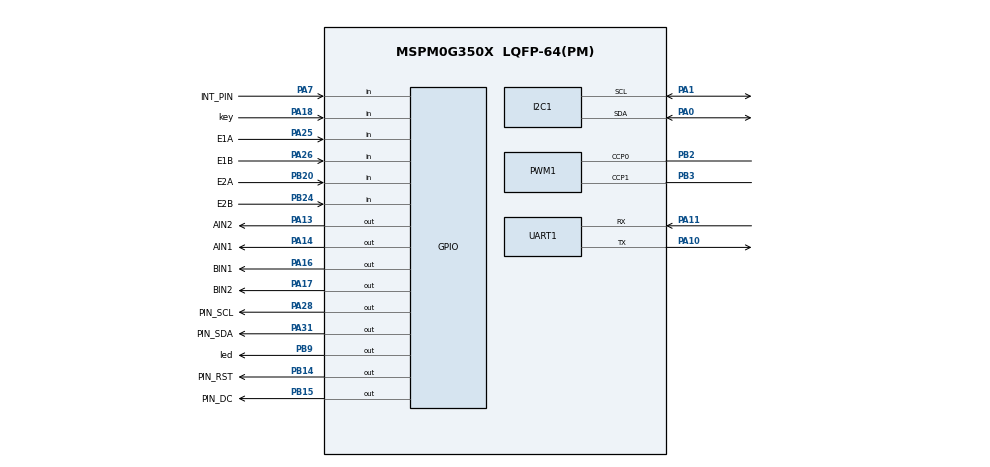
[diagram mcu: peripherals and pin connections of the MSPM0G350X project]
/**
 * @cliArgs --device "MSPM0G350X" --package "LQFP-64(PM)" --part "Default" --product "mspm0_sdk@2.01.00.03"
 * @versions {"tool":"1.20.0+3587"}
 */

/**
 * Import the modules used in this configuration.
 */
const GPIO    = scripting.addModule("/ti/driverlib/GPIO", {}, false);
const GPIO1   = GPIO.addInstance();
const GPIO2   = GPIO.addInstance();
const GPIO3   = GPIO.addInstance();
const GPIO4   = GPIO.addInstance();
const GPIO5   = GPIO.addInstance();
const GPIO6   = GPIO.addInstance();
const GPIO7   = GPIO.addInstance();
const GPIO8   = GPIO.addInstance();
const GPIO9   = GPIO.addInstance();
const GPIO10  = GPIO.addInstance();
const GPIO11  = GPIO.addInstance();
const GPIO12  = GPIO.addInstance();
const GPIO13  = GPIO.addInstance();
const GPIO14  = GPIO.addInstance();
const GPIO15  = GPIO.addInstance();
const I2C     = scripting.addModule("/ti/driverlib/I2C", {}, false);
const I2C1    = I2C.addInstance();
const PWM     = scripting.addModule("/ti/driverlib/PWM", {}, false);
const PWM1    = PWM.addInstance();
const SYSCTL  = scripting.addModule("/ti/driverlib/SYSCTL");
const SYSTICK = scripting.addModule("/ti/driverlib/SYSTICK");
const TIMER   = scripting.addModule("/ti/driverlib/TIMER", {}, false);
const TIMER1  = TIMER.addInstance();
const UART    = scripting.addModule("/ti/driverlib/UART", {}, false);
const UART1   = UART.addInstance();

/**
 * Write custom configuration values to the imported modules.
 */
const divider7       = system.clockTree["PLL_PDIV"];
divider7.divideValue = 2;

const divider9       = system.clockTree["UDIV"];
divider9.divideValue = 2;

const gate7  = system.clockTree["MFCLKGATE"];
gate7.enable = true;

const gate8  = system.clockTree["MFPCLKGATE"];
gate8.enable = true;

const multiplier2         = system.clockTree["PLL_QDIV"];
multiplier2.multiplyValue = 5;

const mux2       = system.clockTree["CANCLKMUX"];
mux2.inputSelect = "CANCLKMUX_PLLCLK1_OUT";

const mux8       = system.clockTree["HSCLKMUX"];
mux8.inputSelect = "HSCLKMUX_SYSPLL2X";

GPIO1.$name                         = "MPU6050";
GPIO1.associatedPins[0].$name       = "INT_PIN";
GPIO1.associatedPins[0].direction   = "INPUT";
GPIO1.associatedPins[0].interruptEn = true;
GPIO1.associatedPins[0].polarity    = "FALL";
GPIO1.associatedPins[0].pin.$assign = "PA7";

const Board = scripting.addModule("/ti/driverlib/Board", {}, false);

GPIO2.$name                               = "ENCODERA";
GPIO2.associatedPins.create(2);
GPIO2.associatedPins[0].$name             = "E1A";
GPIO2.associatedPins[0].direction         = "INPUT";
GPIO2.associatedPins[0].interruptEn       = true;
GPIO2.associatedPins[0].interruptPriority = "0";
GPIO2.associatedPins[0].polarity          = "RISE";
GPIO2.associatedPins[0].pin.$assign       = "PA25";
GPIO2.associatedPins[1].$name             = "E1B";
GPIO2.associatedPins[1].direction         = "INPUT";
GPIO2.associatedPins[1].interruptEn       = true;
GPIO2.associatedPins[1].interruptPriority = "0";
GPIO2.associatedPins[1].polarity          = "RISE";
GPIO2.associatedPins[1].pin.$assign       = "PA26";

GPIO3.$name                               = "ENCODERB";
GPIO3.associatedPins.create(2);
GPIO3.associatedPins[0].direction         = "INPUT";
GPIO3.associatedPins[0].$name             = "E2A";
GPIO3.associatedPins[0].interruptEn       = true;
GPIO3.associatedPins[0].interruptPriority = "0";
GPIO3.associatedPins[0].polarity          = "RISE";
GPIO3.associatedPins[0].pin.$assign       = "PB20";
GPIO3.associatedPins[1].$name             = "E2B";
GPIO3.associatedPins[1].direction         = "INPUT";
GPIO3.associatedPins[1].interruptEn       = true;
GPIO3.associatedPins[1].interruptPriority = "0";
GPIO3.associatedPins[1].polarity          = "RISE";
GPIO3.associatedPins[1].pin.$assign       = "PB24";

GPIO4.$name                         = "AIN";
GPIO4.port                          = "PORTA";
GPIO4.associatedPins.create(2);
GPIO4.associatedPins[0].$name       = "AIN1";
GPIO4.associatedPins[0].pin.$assign = "PA14";
GPIO4.associatedPins[1].$name       = "AIN2";
GPIO4.associatedPins[1].pin.$assign = "PA13";

GPIO5.$name                         = "BIN";
GPIO5.port                          = "PORTA";
GPIO5.associatedPins.create(2);
GPIO5.associatedPins[0].$name       = "BIN1";
GPIO5.associatedPins[0].pin.$assign = "PA16";
GPIO5.associatedPins[1].$name       = "BIN2";
GPIO5.associatedPins[1].pin.$assign = "PA17";

GPIO6.$name                         = "LED";
GPIO6.associatedPins[0].$name       = "led";
GPIO6.associatedPins[0].pin.$assign = "PB9";

GPIO7.$name                         = "KEY";
GPIO7.associatedPins[0].$name       = "key";
GPIO7.associatedPins[0].direction   = "INPUT";
GPIO7.associatedPins[0].pin.$assign = "PA18";

GPIO8.$name                         = "OLED_RST";
GPIO8.associatedPins[0].$name       = "PIN_RST";
GPIO8.associatedPins[0].pin.$assign = "PB14";

GPIO9.$name                         = "OLED_DC";
GPIO9.associatedPins[0].$name       = "PIN_DC";
GPIO9.associatedPins[0].pin.$assign = "PB15";

GPIO10.$name                         = "OLED_SCL";
GPIO10.associatedPins[0].$name       = "PIN_SCL";
GPIO10.associatedPins[0].pin.$assign = "PA28";

GPIO11.$name                         = "OLED_SDA";
GPIO11.associatedPins[0].$name       = "PIN_SDA";
GPIO11.associatedPins[0].pin.$assign = "PA31";

GPIO12.$name                         = "IR_DH4";
GPIO12.port                          = "PORTB";
GPIO12.associatedPins[0].$name       = "PIN_17";
GPIO12.associatedPins[0].direction   = "INPUT";
GPIO12.associatedPins[0].assignedPin = "17";

GPIO13.$name                         = "IR_DH3";
GPIO13.port                          = "PORTB";
GPIO13.associatedPins[0].$name       = "PIN_16";
GPIO13.associatedPins[0].direction   = "INPUT";
GPIO13.associatedPins[0].assignedPin = "16";

GPIO14.$name                         = "IR_DH2";
GPIO14.port                          = "PORTA";
GPIO14.associatedPins[0].direction   = "INPUT";
GPIO14.associatedPins[0].$name       = "PIN_12";
GPIO14.associatedPins[0].assignedPin = "12";

GPIO15.$name                         = "IR_DH1";
GPIO15.port                          = "PORTA";
GPIO15.associatedPins[0].$name       = "PIN_27";
GPIO15.associatedPins[0].direction   = "INPUT";
GPIO15.associatedPins[0].assignedPin = "27";

I2C1.$name                           = "I2C_0";
I2C1.basicEnableController           = true;
I2C1.basicControllerStandardBusSpeed = "Fast";
I2C1.peripheral.$assign              = "I2C0";
I2C1.peripheral.sdaPin.$assign       = "PA0";
I2C1.peripheral.sclPin.$assign       = "PA1";
I2C1.sdaPinConfig.$name              = "ti_driverlib_gpio_GPIOPinGeneric2";
I2C1.sclPinConfig.$name              = "ti_driverlib_gpio_GPIOPinGeneric3";

PWM1.$name                      = "PWM_0";
PWM1.timerStartTimer            = true;
PWM1.pwmMode                    = "EDGE_ALIGN_UP";
PWM1.timerCount                 = 8000;
PWM1.peripheral.$assign         = "TIMA1";
PWM1.peripheral.ccp0Pin.$assign = "PB2";
PWM1.peripheral.ccp1Pin.$assign = "PB3";
PWM1.PWM_CHANNEL_0.$name        = "ti_driverlib_pwm_PWMTimerCC0";
PWM1.PWM_CHANNEL_1.$name        = "ti_driverlib_pwm_PWMTimerCC1";
PWM1.ccp0PinConfig.$name        = "ti_driverlib_gpio_GPIOPinGeneric4";
PWM1.ccp1PinConfig.$name        = "ti_driverlib_gpio_GPIOPinGeneric5";

SYSCTL.forceDefaultClkConfig = true;
SYSCTL.clockTreeEn           = true;

SYSTICK.periodEnable  = true;
SYSTICK.systickEnable = true;
SYSTICK.period        = 16777216;

TIMER1.$name              = "TIMER_0";
TIMER1.timerClkPrescale   = 32;
TIMER1.timerMode          = "PERIODIC";
TIMER1.timerPeriod        = "10 ms";
TIMER1.timerStartTimer    = true;
TIMER1.interrupts         = ["ZERO"];
TIMER1.peripheral.$assign = "TIMG0";

UART1.$name                    = "UART_0";
UART1.profile                  = "CONFIG_PROFILE_1";
UART1.peripheral.$assign       = "UART0";
UART1.peripheral.rxPin.$assign = "PA11";
UART1.peripheral.txPin.$assign = "PA10";
UART1.txPinConfig.$name        = "ti_driverlib_gpio_GPIOPinGeneric0";
UART1.rxPinConfig.$name        = "ti_driverlib_gpio_GPIOPinGeneric1";

/**
 * Pinmux solution for unlocked pins/peripherals. This ensures that minor changes to the automatic solver in a future
 * version of the tool will not impact the pinmux you originally saw.  These lines can be completely deleted in order to
 * re-solve from scratch.
 */
Board.peripheral.$suggestSolution             = "DEBUGSS";
Board.peripheral.swclkPin.$suggestSolution    = "PA20";
Board.peripheral.swdioPin.$suggestSolution    = "PA19";
GPIO12.associatedPins[0].pin.$suggestSolution = "PB17";
GPIO13.associatedPins[0].pin.$suggestSolution = "PB16";
GPIO14.associatedPins[0].pin.$suggestSolution = "PA12";
GPIO15.associatedPins[0].pin.$suggestSolution = "PA27";
